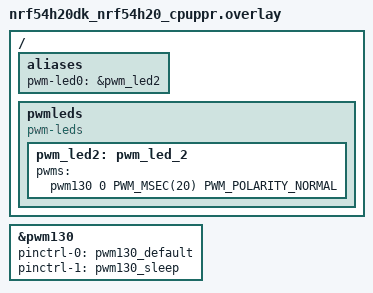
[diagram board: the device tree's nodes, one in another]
#include <zephyr/dt-bindings/pwm/pwm.h>

/ {
	aliases {
		pwm-led0 = &pwm_led2;
	};

	pwmleds {
		compatible = "pwm-leds";
		pwm_led2: pwm_led_2 {
			pwms = <&pwm130 0 PWM_MSEC(20) PWM_POLARITY_NORMAL>;
		};
	};
};

&pwm130 {
	status = "okay";
	pinctrl-0 = <&pwm130_default>;
	pinctrl-1 = <&pwm130_sleep>;
	pinctrl-names = "default", "sleep";
};
